# MK30D7 register map
Vendor: Freescale Semiconductor, Inc.; Series: Kinetis_K; File version: 1.6
CPU: CM4 r0p1, little endian, no MPU, no FPU, VTOR, 4 interrupt priority bits
Registers are 32-bit, read-write, reset 0x0 unless marked. A register's access mark holds for its fields unless they carry their own. Offsets are from the block's base; [hi:lo] are bit positions; {n}, {i} and the like mark numbered series; 'fields as' and 'values as' point back to an identical list.

## FTFL_FlashConfig — Flash configuration field
Base 0x00000400; register names take the prefix NV_
0x00 BACKKEY3 8-bit ro reset 0xFF — Backdoor Comparison Key 3.
  [7:0] KEY — Backdoor Comparison Key.
0x01 BACKKEY2 8-bit ro reset 0xFF — Backdoor Comparison Key 2.
  [7:0] KEY — Backdoor Comparison Key.
0x02 BACKKEY1 8-bit ro reset 0xFF — Backdoor Comparison Key 1.
  [7:0] KEY — Backdoor Comparison Key.
0x03 BACKKEY0 8-bit ro reset 0xFF — Backdoor Comparison Key 0.
  [7:0] KEY — Backdoor Comparison Key.
0x04 BACKKEY7 8-bit ro reset 0xFF — Backdoor Comparison Key 7.
  [7:0] KEY — Backdoor Comparison Key.
0x05 BACKKEY6 8-bit ro reset 0xFF — Backdoor Comparison Key 6.
  [7:0] KEY — Backdoor Comparison Key.
0x06 BACKKEY5 8-bit ro reset 0xFF — Backdoor Comparison Key 5.
  [7:0] KEY — Backdoor Comparison Key.
0x07 BACKKEY4 8-bit ro reset 0xFF — Backdoor Comparison Key 4.
  [7:0] KEY — Backdoor Comparison Key.
0x08 FPROT3 8-bit ro reset 0xFF — Non-volatile P-Flash Protection 1 - Low Register
  [7:0] PROT — P-Flash Region Protect
0x09 FPROT2 8-bit ro reset 0xFF — Non-volatile P-Flash Protection 1 - High Register
  [7:0] PROT — P-Flash Region Protect
0x0A FPROT1 8-bit ro reset 0xFF — Non-volatile P-Flash Protection 0 - Low Register
  [7:0] PROT — P-Flash Region Protect
0x0B FPROT0 8-bit ro reset 0xFF — Non-volatile P-Flash Protection 0 - High Register
  [7:0] PROT — P-Flash Region Protect
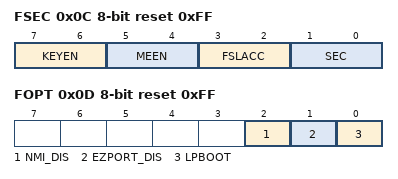
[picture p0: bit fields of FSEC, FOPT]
0x0C FSEC 8-bit ro reset 0xFF — Non-volatile Flash Security Register
  [7:6] KEYEN — Backdoor Key Security Enable
    2=Backdoor key access enabled; 3=Backdoor key access disabled
  [5:4] MEEN
    2=Mass erase is disabled; 3=Mass erase is enabled
  [3:2] FSLACC — Freescale Failure Analysis Access Code
    2=Freescale factory access denied; 3=Freescale factory access granted
  [1:0] SEC — Flash Security
    2=MCU security status is unsecure; 3=MCU security status is secure
0x0D FOPT 8-bit ro reset 0xFF — Non-volatile Flash Option Register
  [2] NMI_DIS
    0=NMI interrupts are always blocked; 1=NMI_b pin/interrupts reset default to enabled
  [1] EZPORT_DIS
    0=EzPort operation is disabled; 1=EzPort operation is enabled
  [0] LPBOOT
    0=Low-power boot; 1=Normal boot
0x0E FEPROT 8-bit ro reset 0xFF — Non-volatile EERAM Protection Register
  [7:0] EPROT
0x0F FDPROT 8-bit ro reset 0xFF — Non-volatile D-Flash Protection Register
  [7:0] DPROT — D-Flash Region Protect

## AIPS0 — AIPS-Lite Bridge
Base 0x40000000; register names take the prefix AIPS0_
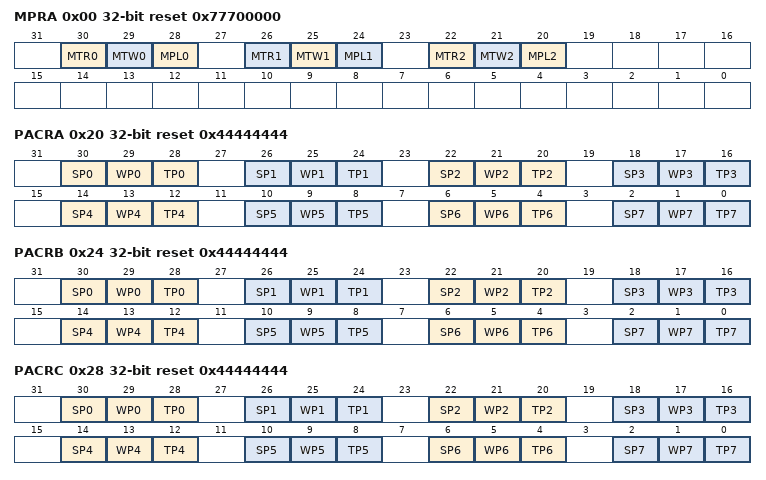
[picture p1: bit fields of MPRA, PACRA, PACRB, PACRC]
0x00 MPRA reset 0x77700000 — Master Privilege Register A
  [30] MTR0 — Master trusted for read
    0=This master is not trusted for read accesses; 1=This master is trusted for read accesses
  [29] MTW0 — Master trusted for writes
    0=This master is not trusted for write accesses; 1=This master is trusted for write accesses
  [28] MPL0 — Master privilege level
    0=Accesses from this master are forced to user-mode; 1=Accesses from this master are not forced to user-mode
  [26] MTR1 — Master trusted for read
    values as MTR0
  [25] MTW1 — Master trusted for writes
    values as MTW0
  [24] MPL1 — Master privilege level
    values as MPL0
  [22] MTR2 — Master trusted for read
    values as MTR0
  [21] MTW2 — Master trusted for writes
    values as MTW0
  [20] MPL2 — Master privilege level
    values as MPL0
0x20 PACRA reset 0x44444444 — Peripheral Access Control Register
  [30-4n] SP{n} (n=0..7) — Supervisor protect
    0=This peripheral does not require supervisor privilege level for accesses; 1=This peripheral requires supervisor privilege level for accesses
  [29-4n] WP{n} (n=0..7) — Write protect
    0=This peripheral allows write accesses; 1=This peripheral is write protected
  [28-4n] TP{n} (n=0..7) — Trusted protect
    0=Accesses from an untrusted master are allowed; 1=Accesses from an untrusted master are not allowed
0x24 PACRB reset 0x44444444 — Peripheral Access Control Register
  fields as PACRA
0x28 PACRC reset 0x44444444 — Peripheral Access Control Register
  fields as PACRA
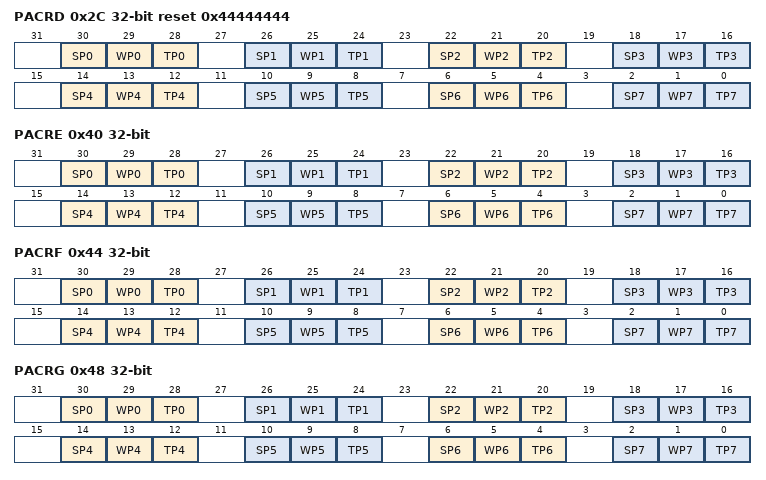
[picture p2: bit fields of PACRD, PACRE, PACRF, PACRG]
0x2C PACRD reset 0x44444444 — Peripheral Access Control Register
  fields as PACRA
0x40 PACRE reset not defined — Peripheral Access Control Register
  fields as PACRA
0x44 PACRF reset not defined — Peripheral Access Control Register
  fields as PACRA
0x48 PACRG reset not defined — Peripheral Access Control Register
  fields as PACRA
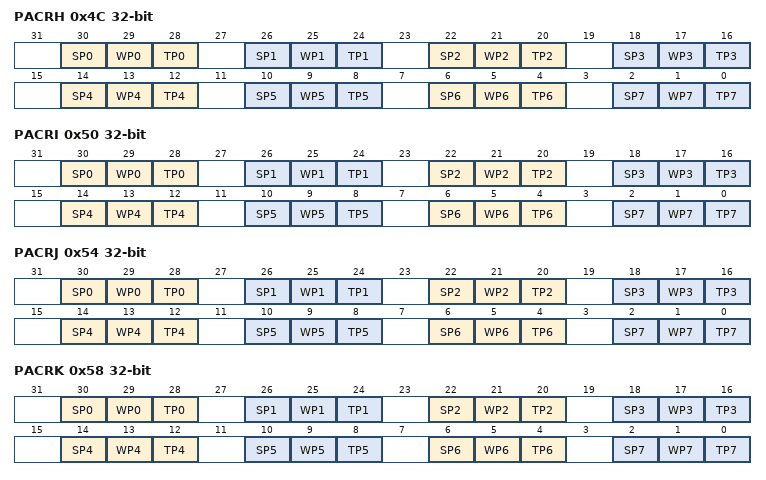
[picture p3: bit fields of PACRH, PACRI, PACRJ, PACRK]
0x4C PACRH reset not defined — Peripheral Access Control Register
  fields as PACRA
0x50 PACRI reset not defined — Peripheral Access Control Register
  fields as PACRA
0x54 PACRJ reset not defined — Peripheral Access Control Register
  fields as PACRA
0x58 PACRK reset not defined — Peripheral Access Control Register
  fields as PACRA
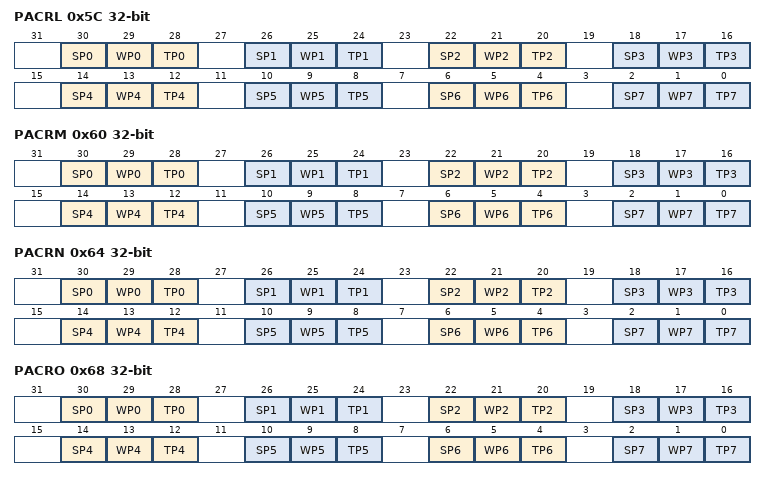
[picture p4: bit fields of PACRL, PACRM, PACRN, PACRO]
0x5C PACRL reset not defined — Peripheral Access Control Register
  fields as PACRA
0x60 PACRM reset not defined — Peripheral Access Control Register
  fields as PACRA
0x64 PACRN reset not defined — Peripheral Access Control Register
  fields as PACRA
0x68 PACRO reset not defined — Peripheral Access Control Register
  fields as PACRA
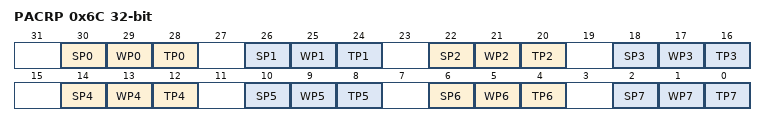
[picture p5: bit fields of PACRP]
0x6C PACRP reset not defined — Peripheral Access Control Register
  fields as PACRA

## AIPS1 — AIPS-Lite Bridge
Base 0x40080000; register names take the prefix AIPS1_
Registers as AIPS0.

## Notices in the file
Redistribution and use in source and binary forms, with or without modification,
are permitted provided that the following conditions are met:
o Redistributions of source code must retain the above copyright notice, this list
of conditions and the following disclaimer.
o Redistributions in binary form must reproduce the above copyright notice, this
list of conditions and the following disclaimer in the documentation and/or
other materials provided with the distribution.
o Neither the name of Freescale Semiconductor, Inc. nor the names of its
contributors may be used to endorse or promote products derived from this
software without specific prior written permission.
THIS SOFTWARE IS PROVIDED BY THE COPYRIGHT HOLDERS AND CONTRIBUTORS "AS IS" AND
ANY EXPRESS OR IMPLIED WARRANTIES, INCLUDING, BUT NOT LIMITED TO, THE IMPLIED
WARRANTIES OF MERCHANTABILITY AND FITNESS FOR A PARTICULAR PURPOSE ARE
DISCLAIMED. IN NO EVENT SHALL THE COPYRIGHT HOLDER OR CONTRIBUTORS BE LIABLE FOR
ANY DIRECT, INDIRECT, INCIDENTAL, SPECIAL, EXEMPLARY, OR CONSEQUENTIAL DAMAGES
(INCLUDING, BUT NOT LIMITED TO, PROCUREMENT OF SUBSTITUTE GOODS OR SERVICES;
LOSS OF USE, DATA, OR PROFITS; OR BUSINESS INTERRUPTION) HOWEVER CAUSED AND ON
ANY THEORY OF LIABILITY, WHETHER IN CONTRACT, STRICT LIABILITY, OR TORT
(INCLUDING NEGLIGENCE OR OTHERWISE) ARISING IN ANY WAY OUT OF THE USE OF THIS
SOFTWARE, EVEN IF ADVISED OF THE POSSIBILITY OF SUCH DAMAGE.
